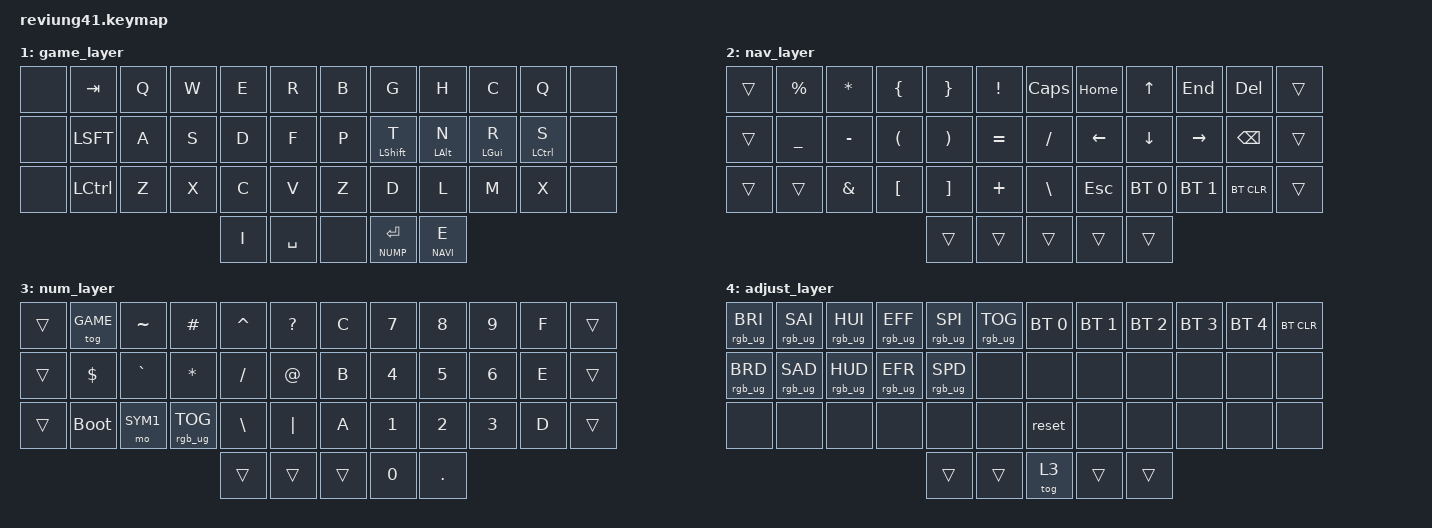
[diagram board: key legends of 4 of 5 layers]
/*
 * Copyright (c) 2020 The ZMK Contributors
 *
 * SPDX-License-Identifier: MIT
 */

#include <behaviors.dtsi>
#include <dt-bindings/zmk/keys.h>
#include <dt-bindings/zmk/bt.h>
#include <dt-bindings/zmk/rgb.h>

#define BASE     0 /* (HANDS DOWN LAYER) */
#define GAME     1 /* (GAME LAYER) */
#define NAVI     2 /* (NAVIGATION LAYER) */
#define NUMP     3 /* (NUMPAD LAYER) */
#define SYM1     4 /* (SYMBOL LAYER 1) */
#define SYM2     5 /* (SYMBOL LAYER 2) */

&lt {
        flavor = "hold-preferred";
};

/ {
        behaviors {
                hm: homerow_mods {
                compatible = "zmk,behavior-hold-tap";
                label = "HOMEROW_MODS";
                #binding-cells = <2>;
                tapping_term_ms = <175>;
                flavor = "tap-preferred";
                bindings = <&kp>, <&kp>;
                };
        };

        keymap {
                compatible = "zmk,keymap";

                beakl_15_inspired {
// -----------------------------------------------------------------------------------------
// | ESC |  Q  |  H  |  O  |  U  |  X  |     |  G  |  C  |  R  |  F  |  Z  | BSPC|
// |     |  Y  |  I  |  E  |  A  |  ;  |     |  D  |  S  |  T  |  N  |  B  |     |
// |     |  '  |  ,  |  J  |  K  |  .  |     |  W  |  M  |  L  |  P  |  V  |     |
//                         | TAB | ENT |     | SPC | BSPC|
                        bindings = <
   &kp ESC &kp Q       &kp H      &kp O        &kp U        &kp X                &kp G          &kp C         &kp R         &kp F      &kp Z       &kp BSPC
   &none   &hm LCTRL Y &hm LGUI I &hm LALT E   &hm LSHFT A  &kp SEMI             &kp D          &hm LSHFT S   &hm LALT T    &hm LGUI N &hm LCTRL B &none
   &none   &kp APOS    &kp COMMA  &kp J        &kp K        &kp DOT              &kp W          &kp M         &kp L         &kp P      &kp V       &none
                                               &lt NAVI TAB &lt NUMP RET  &none  &lt NAVI SPACE &lt NUMP BSPC &none
                        >;
                };

                game_layer {
// -----------------------------------------------------------------------------------------
// |     | TAB |  Q  |  W  |  E  |  R  |     |  B  |  G  |  H  |  C  |  Q  |     |
// |     | SHFT|  A  |  S  |  D  |  F  |     |  P  |  T  |  N  |  R  |  S  |     |
// |     | CTRL|  Z  |  X  |  C  |  V  |     |  Z  |  D  |  L  |  M  |  X  |     |
//                         |  I  | SPC |     | RET |  E  |
                        bindings = <
   &none  &kp TAB    &kp Q  &kp W &kp E &kp R             &kp B        &kp G       &kp H      &kp C      &kp Q        &none
   &none  &kp LSFT   &kp A  &kp S &kp D &kp F             &kp P        &hm LSHFT T &hm LALT N &hm LGUI R &hm LCTRL S  &none
   &none  &kp LCTRL  &kp Z  &kp X &kp C &kp V             &kp Z        &kp D       &kp L      &kp M      &kp X        &none
                                  &kp I &kp SPACE  &none  &lt NUMP RET &lt NAVI E
                        >;
                };

                nav_layer {
// -----------------------------------------------------------------------------------------
// |     |  %  |  *  |  {  |  }  |  !  |     | CAPS| HOME |  UP  | END  | DEL  |     |
// |     |  _  |  -  |  (  |  )  |  =  |     |  /  | LEFT | DOWN | RGT  | BKSP |     |
// |     |     |  &  |  [  |  ]  |  +  |     |  \  | ESC  | BT_1 | BT_2 | BCLR |     |
//                         |     |     |     |     |      |
                        bindings = <
   &trans &kp PRCNT &kp STAR  &kp LBRC &kp RBRC &kp EXCL            &kp CAPS &kp HOME &kp UP       &kp END      &kp DEL    &trans
   &trans &kp UNDER &kp MINUS &kp LPAR &kp RPAR &kp EQUAL           &kp FSLH &kp LEFT &kp DOWN     &kp RIGHT    &kp BSPC   &trans
   &trans &trans    &kp AMPS  &kp LBKT &kp RBKT &kp PLUS            &kp BSLH &kp ESC  &bt BT_SEL 0 &bt BT_SEL 1 &bt BT_CLR &trans
                                       &trans   &trans    &trans    &trans   &trans
                        >;
                };

                num_layer {
// -----------------------------------------------------------------------------------------
// |     | GME |  ~  |  #  |  ^  |  ?  |     |  C  |  7  |  8  |  9  |  F  |     |
// |     |  $  |  `  |  *  |  /  |  @  |     |  B  |  4  |  5  |  6  |  E  |     |
// |     | BOOT| SYM1| RGB |  \  | "|" |     |  A  |  1  |  2  |  3  |  D  |     |
//                         |     |     |     |  0  |  .  |
                        bindings = <
   &trans &tog GAME   &kp TILDE &kp HASH           &kp CARET &kp QMARK         &kp C  &kp N7   &kp N8  &kp N9  &kp F &trans
   &trans &kp DLLR    &kp GRAVE &kp STAR           &kp FSLH  &kp AT            &kp B  &kp N4   &kp N5  &kp N6  &kp E &trans
   &trans &bootloader &mo SYM1  &rgb_ug RGB_TOG    &kp BSLH  &kp PIPE          &kp A  &kp N1   &kp N2  &kp N3  &kp D &trans
                                                   &trans    &trans    &trans  &kp N0 &kp DOT
                        >;
                };

                adjust_layer {
// -----------------------------------------------------------------------------------------
// | RGB BRI+ | RGB SAT+ | RGB HUE+ | RGB ANI+ | RGB SPI | RGB TOG |     |  BT1  | BT2 | BT3 | BT4 | BT5 | BT CLR |
// | RGB BRI- | RGB SAT- | RGB HUE- | RGB ANI+ | RGB SPD |         |     |       |     |     |     |     |        |
// |          |          |          |          |    |         |     | RESET |     |     |     |     |        |
//                                             |    |         |     |       |     |
                        bindings = <
   &rgb_ug RGB_BRI &rgb_ug RGB_SAI &rgb_ug RGB_HUI &rgb_ug RGB_EFF &rgb_ug RGB_SPI &rgb_ug RGB_TOG           &bt BT_SEL 0 &bt BT_SEL 1 &bt BT_SEL 2 &bt BT_SEL 3 &bt BT_SEL 4 &bt BT_CLR
   &rgb_ug RGB_BRD &rgb_ug RGB_SAD &rgb_ug RGB_HUD &rgb_ug RGB_EFR &rgb_ug RGB_SPD &none                     &none        &none        &none        &none        &none        &none
   &none           &none           &none           &none           &none           &none                     &reset       &none        &none        &none        &none        &none
                                                                   &trans          &trans           &tog 3   &trans       &trans
                        >;
                };
        };
};
